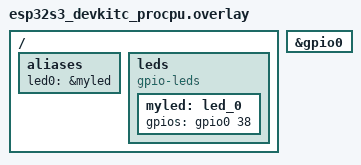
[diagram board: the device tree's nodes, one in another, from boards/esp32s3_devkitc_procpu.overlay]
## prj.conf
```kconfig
CONFIG_GPIO=y
# CONFIG_LED_STRIP=y
#  # Explicitly compile the GPIO bit-bang driver backend
# CONFIG_WS2812_STRIP_GPIO=y
CONFIG_PRINTK=y
```

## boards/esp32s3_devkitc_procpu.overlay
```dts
/ {
    aliases {
        led0 = &myled;
    };
};

&gpio0 {
    status = "okay";
};

/ {
    leds {
        compatible = "gpio-leds";
        myled: led_0 {
            gpios = <&gpio0 38 GPIO_ACTIVE_HIGH>; // change pin to your board's LED pin
        };
    };
 };
// #include <zephyr/dt-bindings/gpio/gpio.h>
// #include <zephyr/dt-bindings/led/led.h>
// / {
//     aliases {
//         led-strip = &led_strip;
//     };
// };

// &gpio0 {
//     status = "okay";
// };

// /* Define the WS2812 pin controller */
// &gpio0 {
//     led_strip: ws2812 {
//         compatible = "worldsemi,ws2812-gpio";
//         /* Change to 48 if you have an older v1.0 board */
//         gpios = <&gpio0 38 GPIO_ACTIVE_HIGH>; 
//         chain-length = <1>; /* Onboard has exactly 1 RGB LED */
//         color-mapping = <LED_COLOR_CHANNELS_GRB>;
//         status = "okay";
//     };
// };

// / {
//     aliases {
//         led-strip = &led_strip;
//     };
// };

// &gpio0 {
//     status = "okay";
// };

// &gpio0 {
//     led_strip: ws2812 {
//         /* Swap to RMT compatible driver mapping */
//         compatible = "worldsemi,ws2812-rmt";
//         gpios = <&gpio0 38 0>; 
//         chain-length = <1>; 
//         color-mapping = <2 1 3>;
//         status = "okay";
//     };
// };

// / {
//     aliases {
//         led-strip = &led_strip;
//     };
// };

// &gpio0 {
//     status = "okay";
// };

// &gpio0 {
//     led_strip: ws2812 {
//         compatible = "worldsemi,ws2812-gpio";
//         /* 38 is the GPIO pin, 0 means GPIO_ACTIVE_HIGH */
//         gpios = <&gpio0 38 0>; 
//         chain-length = <1>; 
//         /* 2 = Green, 1 = Red, 3 = Blue */
//         color-mapping = <2 1 3>;
//         status = "okay";
//     };
// };
```

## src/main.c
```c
#include <zephyr/kernel.h>
#include <zephyr/drivers/gpio.h>
#include <zephyr/sys/printk.h>

#define LED0_NODE DT_ALIAS(led0)

static const struct gpio_dt_spec led = GPIO_DT_SPEC_GET(LED0_NODE, gpios);

int main(void)
{
    if (!gpio_is_ready_dt(&led)) {
        printk("LED device not ready\n");
        return 0;
    }

    gpio_pin_configure_dt(&led, GPIO_OUTPUT_ACTIVE);

    while (1) {
        gpio_pin_toggle_dt(&led);
        printk("Toggled LED\n");
        k_msleep(500);
    }
    return 0;
}

// #include <zephyr/kernel.h>
// #include <zephyr/drivers/led_strip.h>
// #include <zephyr/device.h>
// #include <zephyr/sys/util.h>

// #define STRIP_NODE DT_ALIAS(led_strip)

// #if !DT_NODE_HAS_STATUS_OKAY(STRIP_NODE)
// #error "Unsupported board: led-strip alias is not defined or enabled"
// #endif

// // Fetch device reference from devicetree
// static const struct device *const strip = DEVICE_DT_GET(STRIP_NODE);

// // Prepare color buffer structure (1 pixel)
// static struct led_rgb pixels[1];

// int main(void)
// {
//     if (!device_is_ready(strip)) {
//         printk("LED strip device %s is not ready\n", strip->name);
//         return 0;
//     }

//     while (1) {
//         // 1. Red Blink
//         pixels[0].r = 255; pixels[0].g = 0; pixels[0].b = 0;
//         led_strip_update_rgb(strip, pixels, 1);
//         k_msleep(1000);

//         // 2. Green Blink
//         pixels[0].r = 0; pixels[0].g = 255; pixels[0].b = 0;
//         led_strip_update_rgb(strip, pixels, 1);
//         k_msleep(1000);

//         // 3. Blue Blink
//         pixels[0].r = 0; pixels[0].g = 0; pixels[0].b = 255;
//         led_strip_update_rgb(strip, pixels, 1);
//         k_msleep(1000);

//         // 4. Turn Off
//         pixels[0].r = 0; pixels[0].g = 0; pixels[0].b = 0;
//         led_strip_update_rgb(strip, pixels, 1);
//         k_msleep(1000);
//     }
//     return 0;
// }
```
